AUTOSAR XML (schema 4-3-0)
package /ComponentTypes
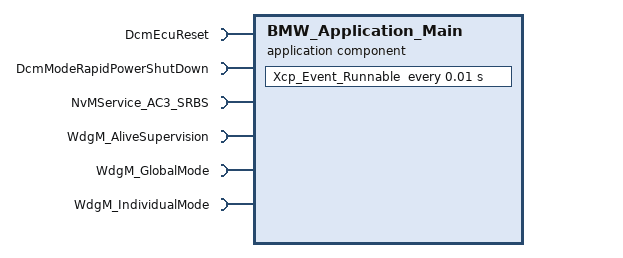
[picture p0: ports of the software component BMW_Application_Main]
  application sw component type BMW_Application_Main
    6 x require port:
      DcmEcuReset: mode-switch-receiver-com-spec{enhanced-mode-api=false, supports-asynchronous-mode-switch=false}, required-interface=DcmEcuReset
      DcmModeRapidPowerShutDown: mode-switch-receiver-com-spec{enhanced-mode-api=false, supports-asynchronous-mode-switch=false}, required-interface=DcmModeRapidPowerShutDown
      NvMService_AC3_SRBS: required-interface=NvMService_AC3_SRBS
      WdgM_AliveSupervision: required-interface=WdgM_AliveSupervision
      WdgM_GlobalMode: mode-switch-receiver-com-spec{enhanced-mode-api=false, supports-asynchronous-mode-switch=false}, required-interface=WdgM_GlobalMode
      WdgM_IndividualMode: mode-switch-receiver-com-spec{enhanced-mode-api=false, supports-asynchronous-mode-switch=false}, required-interface=WdgM_IndividualMode
    behavior BMW_Application_Main_InternalBehavior: data-type-mapping=TMS_Bac4_ApplicationState
      ar-typed-per-instance-memorys:
        data PerInstanceMemory_Xcp: sw-calibration-access=READ-ONLY, type=uint32
      5 x swc mode switch event, all with activation=ON-ENTRY:
        MST_Dcm_BAC4_EcuReset_0: start-on-event=Dcm_BAC4_EcuReset_Execute, mode=DcmEcuReset.DcmEcuReset.EXECUTE
        MST_Dcm_BAC4_EcuReset_Hard_0: start-on-event=Dcm_BAC4_EcuReset_Hard, mode=DcmEcuReset.DcmEcuReset.HARD
        MST_Runnable_0: start-on-event=Dcm_BAC4_Jump2Boot, mode=DcmEcuReset.DcmEcuReset.JUMPTOBOOTLOADER
        MST_Dcm_BAC4_RapidShutdownDisable_0: start-on-event=Dcm_BAC4_RapidShutdownDisable, mode=DcmModeRapidPowerShutDown.DcmModeRapidPowerShutDown.DISABLE_RAPIDPOWERSHUTDOWN
        MST_Dcm_BAC4_RapidShutdownEnable_0: start-on-event=Dcm_BAC4_RapidShutdownEnable, mode=DcmModeRapidPowerShutDown.DcmModeRapidPowerShutDown.ENABLE_RAPIDPOWERSHUTDOWN
      timing event TMT_Xcp_Event_Runnable: start-on-event=Xcp_Event_Runnable, period=0.01
      explicit-inter-runnable-variables:
        data InterRunnableVariable: type=BMW_Application_Reset_IRV, init-value=0
      port-api-options:
        enable-take-address=false, error-handling=NO-TRANSFORMER-ERROR-HANDLING, indirect-api=false, port=DcmEcuReset
        enable-take-address=false, error-handling=NO-TRANSFORMER-ERROR-HANDLING, indirect-api=false, port=NvMService_AC3_SRBS
        enable-take-address=false, error-handling=NO-TRANSFORMER-ERROR-HANDLING, indirect-api=false, port=WdgM_AliveSupervision
        enable-take-address=false, error-handling=NO-TRANSFORMER-ERROR-HANDLING, indirect-api=false, port=WdgM_GlobalMode
        enable-take-address=false, error-handling=NO-TRANSFORMER-ERROR-HANDLING, indirect-api=false, port=WdgM_IndividualMode
      6 x runnable:
        Dcm_BAC4_EcuReset_Execute: mode-access-point=DcmEcuReset.DcmEcuReset
          read-local-variables:
            access READ_InterRunnableVariable: accessed-variable=InterRunnableVariable
        Dcm_BAC4_EcuReset_Hard: mode-access-point=DcmEcuReset.DcmEcuReset
          written-local-variables:
            access WRITE_InterRunnableVariable: accessed-variable=InterRunnableVariable
        Dcm_BAC4_Jump2Boot: mode-access-point=DcmEcuReset.DcmEcuReset
          written-local-variables:
            access WRITE_InterRunnableVariable: accessed-variable=InterRunnableVariable
        Dcm_BAC4_RapidShutdownDisable: mode-access-point=DcmModeRapidPowerShutDown.DcmModeRapidPowerShutDown
        Dcm_BAC4_RapidShutdownEnable: mode-access-point=DcmModeRapidPowerShutDown.DcmModeRapidPowerShutDown
        Xcp_Event_Runnable
  swc implementation BMW_Application_Main_Implementation: behavior=BMW_Application_Main_InternalBehavior
    code-descriptors:
      code Default: artifact-descriptors=autosar-engineering-object={short-label=Default, category=SWSRC}
